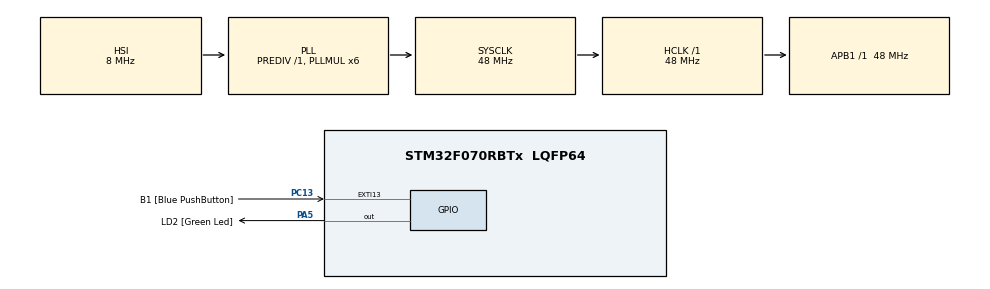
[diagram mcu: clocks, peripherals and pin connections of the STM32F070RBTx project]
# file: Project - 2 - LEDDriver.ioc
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Mcu.Family=STM32F0
Mcu.Name=STM32F070RBTx
Mcu.Package=LQFP64
PA13.GPIO_Label=TMS
PA13.Signal=SYS_SWDIO
PA2.GPIO_Label=USART_TX
PA2.Signal=USART2_TX
PA3.GPIO_Label=USART_RX
PA3.Signal=USART2_RX
PA5.GPIO_Label=LD2 [Green Led]
PA5.Signal=GPIO_Output
PC13.GPIO_Label=B1 [Blue PushButton]
PC13.GPIO_ModeDefaultEXTI=GPIO_MODE_IT_FALLING
PC13.Signal=GPXTI13
PC14-OSC32_IN.GPIO_Label=RCC_OSC32_IN
PC14-OSC32_IN.Signal=RCC_OSC32_IN
PC15-OSC32_OUT.GPIO_Label=RCC_OSC32_OUT
PC15-OSC32_OUT.Signal=RCC_OSC32_OUT
PF0-OSC_IN.GPIO_Label=RCC_OSC_IN
PF0-OSC_IN.Signal=RCC_OSC_IN
PF1-OSC_OUT.GPIO_Label=RCC_OSC_OUT
PF1-OSC_OUT.Signal=RCC_OSC_OUT
ProjectManager.HeapSize=0x200
ProjectManager.StackSize=0x400
ProjectManager.TargetToolchain=STM32CubeIDE
RCC.AHBFreq_Value=48000000
RCC.APB1Freq_Value=48000000
RCC.APB1TimFreq_Value=48000000
RCC.HCLKFreq_Value=48000000
RCC.PLLMUL=RCC_PLL_MUL6
RCC.SYSCLKFreq_VALUE=48000000
RCC.SYSCLKSource=RCC_SYSCLKSOURCE_PLLCLK
board=NUCLEO-F070RB

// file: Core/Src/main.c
/* USER CODE BEGIN Header */
/**
  ******************************************************************************
  * @file           : main.c
  * @brief          : Main program body
  ******************************************************************************
  * @attention
  *
  * <h2><center>&copy; Copyright (c) 2020 STMicroelectronics.
  * All rights reserved.</center></h2>
  *
  * This software component is licensed by ST under BSD 3-Clause license,
  * the "License"; You may not use this file except in compliance with the
  * License. You may obtain a copy of the License at:
  *                        opensource.org/licenses/BSD-3-Clause
  *
  ******************************************************************************
  */
/* USER CODE END Header */

#include "main.h"

void SystemClock_Config(void);

int main(void)
{

  /* MCU Configuration--------------------------------------------------------*/

  /* Reset of all peripherals, Initializes the Flash interface and the Systick. */
  HAL_Init();

  /* Configure the system clock */
  SystemClock_Config();

  /* USER CODE BEGIN 2 */
	user_led_init();
  /* USER CODE END 2 */

  /* Infinite loop */
  while (1)
  {

    /* USER CODE BEGIN 3 */
	  user_led_set();
	  HAL_Delay(1000);
	  user_led_reset();
	  HAL_Delay(1000);
  }
  /* USER CODE END 3 */
}

void SystemClock_Config(void)
{
  RCC_OscInitTypeDef RCC_OscInitStruct = {0};
  RCC_ClkInitTypeDef RCC_ClkInitStruct = {0};

  /** Initializes the CPU, AHB and APB busses clocks
  */
  RCC_OscInitStruct.OscillatorType = RCC_OSCILLATORTYPE_HSI;
  RCC_OscInitStruct.HSIState = RCC_HSI_ON;
  RCC_OscInitStruct.HSICalibrationValue = RCC_HSICALIBRATION_DEFAULT;
  RCC_OscInitStruct.PLL.PLLState = RCC_PLL_ON;
  RCC_OscInitStruct.PLL.PLLSource = RCC_PLLSOURCE_HSI;
  RCC_OscInitStruct.PLL.PLLMUL = RCC_PLL_MUL6;
  RCC_OscInitStruct.PLL.PREDIV = RCC_PREDIV_DIV1;
  if (HAL_RCC_OscConfig(&RCC_OscInitStruct) != HAL_OK)
  {
    Error_Handler();
  }
  /** Initializes the CPU, AHB and APB busses clocks
  */
  RCC_ClkInitStruct.ClockType = RCC_CLOCKTYPE_HCLK|RCC_CLOCKTYPE_SYSCLK
                              |RCC_CLOCKTYPE_PCLK1;
  RCC_ClkInitStruct.SYSCLKSource = RCC_SYSCLKSOURCE_PLLCLK;
  RCC_ClkInitStruct.AHBCLKDivider = RCC_SYSCLK_DIV1;
  RCC_ClkInitStruct.APB1CLKDivider = RCC_HCLK_DIV1;

  if (HAL_RCC_ClockConfig(&RCC_ClkInitStruct, FLASH_LATENCY_1) != HAL_OK)
  {
    Error_Handler();
  }
}

void Error_Handler(void)
{
}

/************************ (C) COPYRIGHT STMicroelectronics *****END OF FILE****/
